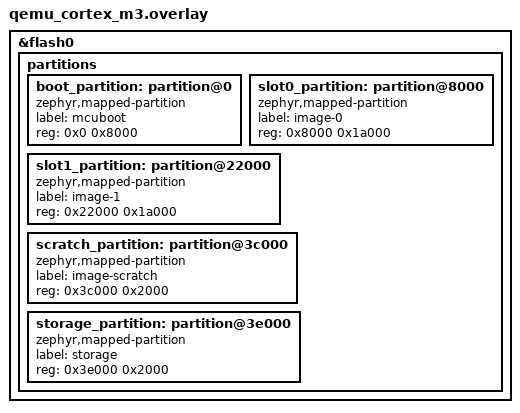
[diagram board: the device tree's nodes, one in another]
/*
 * Copyright (c) 2026 Nordic Semiconductor ASA
 *
 * SPDX-License-Identifier: LicenseRef-Nordic-5-Clause
 */

&flash0 {
	partitions {
		ranges;
		#address-cells = <1>;
		#size-cells = <1>;

		boot_partition: partition@0 {
			compatible = "zephyr,mapped-partition";
			label = "mcuboot";
			reg = <0x0 0x8000>;
		};

		slot0_partition: partition@8000 {
			compatible = "zephyr,mapped-partition";
			label = "image-0";
			reg = <0x8000 0x1a000>;
		};

		slot1_partition: partition@22000 {
			compatible = "zephyr,mapped-partition";
			label = "image-1";
			reg = <0x22000 0x1a000>;
		};

		scratch_partition: partition@3c000 {
			compatible = "zephyr,mapped-partition";
			label = "image-scratch";
			reg = <0x3c000 0x2000>;
		};

		storage_partition: partition@3e000 {
			compatible = "zephyr,mapped-partition";
			label = "storage";
			reg = <0x3e000 0x2000>;
		};
	};
};
